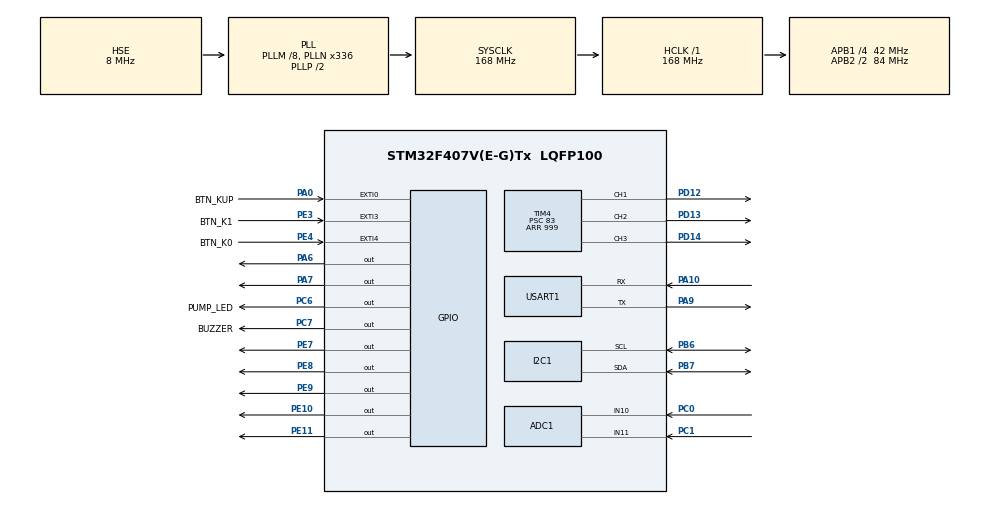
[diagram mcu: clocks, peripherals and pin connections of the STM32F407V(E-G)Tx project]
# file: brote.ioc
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ADC1.Channel-2\#ChannelRegularConversion=ADC_CHANNEL_10
ADC1.NbrOfConversionFlag=1
ADC1.Rank-2\#ChannelRegularConversion=1
ADC1.SamplingTime-2\#ChannelRegularConversion=ADC_SAMPLETIME_3CYCLES
ADC1.master=1
Dma.Request0=USART1_TX
Dma.USART1_TX.0.Direction=DMA_MEMORY_TO_PERIPH
Dma.USART1_TX.0.FIFOMode=DMA_FIFOMODE_DISABLE
Dma.USART1_TX.0.Instance=DMA2_Stream7
Dma.USART1_TX.0.MemDataAlignment=DMA_MDATAALIGN_BYTE
Dma.USART1_TX.0.MemInc=DMA_MINC_ENABLE
Dma.USART1_TX.0.Mode=DMA_NORMAL
Dma.USART1_TX.0.PeriphDataAlignment=DMA_PDATAALIGN_BYTE
Dma.USART1_TX.0.PeriphInc=DMA_PINC_DISABLE
Dma.USART1_TX.0.Priority=DMA_PRIORITY_LOW
FREERTOS.Mutexes01=mtxI2C,Dynamic,NULL,Available;mtxData,Dynamic,NULL,Available
FREERTOS.Queues01=qEvents,8,app_event_t,0,Dynamic,NULL,NULL;qLog,16,log_msg_t,0,Dynamic,NULL,NULL
FREERTOS.Tasks01=tActuators,40,256,StartActuatorsTask,As weak,NULL,Dynamic,NULL,NULL;tControl,32,256,StartControlTask,As weak,NULL,Dynamic,NULL,NULL;tSensors,24,256,StartSensorsTask,As weak,NULL,Dynamic,NULL,NULL;tDisplay,16,384,StartDisplayTask,As weak,NULL,Dynamic,NULL,NULL;tLogger,8,384,StartLoggerTask,As weak,NULL,Dynamic,NULL,NULL
FREERTOS.configCHECK_FOR_STACK_OVERFLOW=2
FREERTOS.configTOTAL_HEAP_SIZE=32768
FREERTOS.configUSE_NEWLIB_REENTRANT=1
I2C1.I2C_Mode=I2C_Fast
Mcu.Family=STM32F4
Mcu.Name=STM32F407V(E-G)Tx
Mcu.Package=LQFP100
NVIC.DMA2_Stream7_IRQn=true\:5\:0\:false\:false\:true\:true\:false\:true\:true
NVIC.EXTI0_IRQn=true\:6\:0\:true\:false\:true\:true\:true\:true\:true
NVIC.EXTI3_IRQn=true\:6\:0\:true\:false\:true\:true\:true\:true\:true
NVIC.EXTI4_IRQn=true\:6\:0\:true\:false\:true\:true\:true\:true\:true
NVIC.PriorityGroup=NVIC_PRIORITYGROUP_4
NVIC.TimeBase=TIM6_DAC_IRQn
NVIC.TimeBaseIP=TIM6
NVIC.USART1_IRQn=true\:5\:0\:false\:false\:true\:true\:false\:true\:true
PA0-WKUP.GPIO_Label=BTN_KUP
PA0-WKUP.GPIO_ModeDefaultEXTI=GPIO_MODE_IT_RISING
PA0-WKUP.GPIO_PuPd=GPIO_PULLDOWN
PA0-WKUP.Signal=GPXTI0
PA10.Mode=Asynchronous
PA10.Signal=USART1_RX
PA13.Mode=Serial_Wire
PA13.Signal=SYS_JTMS-SWDIO
PA14.Mode=Serial_Wire
PA14.Signal=SYS_JTCK-SWCLK
PA6.PinState=GPIO_PIN_SET
PA6.Signal=GPIO_Output
PA7.PinState=GPIO_PIN_SET
PA7.Signal=GPIO_Output
PA9.Mode=Asynchronous
PA9.Signal=USART1_TX
PB6.Mode=I2C
PB6.Signal=I2C1_SCL
PB7.Mode=I2C
PB7.Signal=I2C1_SDA
PC0.Signal=ADCx_IN10
PC1.Signal=ADCx_IN11
PC6.GPIO_Label=PUMP_LED
PC6.Signal=GPIO_Output
PC7.GPIO_Label=BUZZER
PC7.PinState=GPIO_PIN_SET
PC7.Signal=GPIO_Output
PD12.Signal=S_TIM4_CH1
PD13.Signal=S_TIM4_CH2
PD14.Signal=S_TIM4_CH3
PE10.Signal=GPIO_Output
PE11.Signal=GPIO_Output
PE3.GPIO_Label=BTN_K1
PE3.GPIO_ModeDefaultEXTI=GPIO_MODE_IT_FALLING
PE3.GPIO_PuPd=GPIO_PULLUP
PE3.Signal=GPXTI3
PE4.GPIO_Label=BTN_K0
PE4.GPIO_ModeDefaultEXTI=GPIO_MODE_IT_FALLING
PE4.GPIO_PuPd=GPIO_PULLUP
PE4.Signal=GPXTI4
PE7.Signal=GPIO_Output
PE8.Signal=GPIO_Output
PE9.Signal=GPIO_Output
PH0-OSC_IN.Mode=HSE-External-Oscillator
PH0-OSC_IN.Signal=RCC_OSC_IN
PH1-OSC_OUT.Mode=HSE-External-Oscillator
PH1-OSC_OUT.Signal=RCC_OSC_OUT
ProjectManager.HeapSize=0x200
ProjectManager.StackSize=0x400
ProjectManager.TargetToolchain=STM32CubeIDE
RCC.48MHZClocksFreq_Value=84000000
RCC.AHBFreq_Value=168000000
RCC.APB1CLKDivider=RCC_HCLK_DIV4
RCC.APB1Freq_Value=42000000
RCC.APB1TimFreq_Value=84000000
RCC.APB2CLKDivider=RCC_HCLK_DIV2
RCC.APB2Freq_Value=84000000
RCC.APB2TimFreq_Value=168000000
RCC.CortexFreq_Value=168000000
RCC.EnbaleCSS=true
RCC.HCLKFreq_Value=168000000
RCC.HSE_VALUE=8000000
RCC.HSI_VALUE=16000000
RCC.LSE_VALUE=32768
RCC.PLLM=8
RCC.PLLN=336
RCC.PLLSourceVirtual=RCC_PLLSOURCE_HSE
RCC.SYSCLKFreq_VALUE=168000000
RCC.SYSCLKSource=RCC_SYSCLKSOURCE_PLLCLK
RCC.VCOOutputFreq_Value=336000000
SH.ADCx_IN10.0=ADC1_IN10,IN10
SH.ADCx_IN11.0=ADC1_IN11,IN11
SH.S_TIM4_CH1.0=TIM4_CH1,PWM Generation1 CH1
SH.S_TIM4_CH2.0=TIM4_CH2,PWM Generation2 CH2
SH.S_TIM4_CH3.0=TIM4_CH3,PWM Generation3 CH3
TIM4.Channel-PWM\ Generation1\ CH1=TIM_CHANNEL_1
TIM4.Channel-PWM\ Generation2\ CH2=TIM_CHANNEL_2
TIM4.Channel-PWM\ Generation3\ CH3=TIM_CHANNEL_3
TIM4.Period=999
TIM4.Prescaler=83
USART1.VirtualMode=VM_ASYNC
VP_FREERTOS_VS_CMSIS_V2.Mode=CMSIS_V2
VP_SYS_VS_tim6.Mode=TIM6
board=custom

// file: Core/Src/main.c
/* USER CODE BEGIN Header */
/**
  ******************************************************************************
  * @file           : main.c
  * @brief          : Main program body
  ******************************************************************************
  * @attention
  *
  * Copyright (c) 2026 STMicroelectronics.
  * All rights reserved.
  *
  * This software is licensed under terms that can be found in the LICENSE file
  * in the root directory of this software component.
  * If no LICENSE file comes with this software, it is provided AS-IS.
  *
  ******************************************************************************
  */
/* USER CODE END Header */
#include "main.h"
#include "cmsis_os.h"
#include "adc.h"
#include "dma.h"
#include "i2c.h"
#include "tim.h"
#include "usart.h"
#include "gpio.h"

void SystemClock_Config(void);
void MX_FREERTOS_Init(void);

int main(void)
{

  /* MCU Configuration--------------------------------------------------------*/

  /* Reset of all peripherals, Initializes the Flash interface and the Systick. */
  HAL_Init();

  /* Configure the system clock */
  SystemClock_Config();

  /* Initialize all configured peripherals */
  MX_GPIO_Init();
  MX_DMA_Init();
  MX_ADC1_Init();
  MX_USART1_UART_Init();
  MX_I2C1_Init();
  MX_TIM4_Init();

  /* Init scheduler */
  osKernelInitialize();  /* Call init function for freertos objects (in cmsis_os2.c) */
  MX_FREERTOS_Init();

  /* Start scheduler */
  osKernelStart();

  /* We should never get here as control is now taken by the scheduler */

  /* Infinite loop */
  while (1)
  {

  }
}

void SystemClock_Config(void)
{
  RCC_OscInitTypeDef RCC_OscInitStruct = {0};
  RCC_ClkInitTypeDef RCC_ClkInitStruct = {0};

  /** Configure the main internal regulator output voltage
  */
  __HAL_RCC_PWR_CLK_ENABLE();
  __HAL_PWR_VOLTAGESCALING_CONFIG(PWR_REGULATOR_VOLTAGE_SCALE1);

  /** Initializes the RCC Oscillators according to the specified parameters
  * in the RCC_OscInitTypeDef structure.
  */
  RCC_OscInitStruct.OscillatorType = RCC_OSCILLATORTYPE_HSE;
  RCC_OscInitStruct.HSEState = RCC_HSE_ON;
  RCC_OscInitStruct.PLL.PLLState = RCC_PLL_ON;
  RCC_OscInitStruct.PLL.PLLSource = RCC_PLLSOURCE_HSE;
  RCC_OscInitStruct.PLL.PLLM = 8;
  RCC_OscInitStruct.PLL.PLLN = 336;
  RCC_OscInitStruct.PLL.PLLP = RCC_PLLP_DIV2;
  RCC_OscInitStruct.PLL.PLLQ = 4;
  if (HAL_RCC_OscConfig(&RCC_OscInitStruct) != HAL_OK)
  {
    Error_Handler();
  }

  /** Initializes the CPU, AHB and APB buses clocks
  */
  RCC_ClkInitStruct.ClockType = RCC_CLOCKTYPE_HCLK|RCC_CLOCKTYPE_SYSCLK
                              |RCC_CLOCKTYPE_PCLK1|RCC_CLOCKTYPE_PCLK2;
  RCC_ClkInitStruct.SYSCLKSource = RCC_SYSCLKSOURCE_PLLCLK;
  RCC_ClkInitStruct.AHBCLKDivider = RCC_SYSCLK_DIV1;
  RCC_ClkInitStruct.APB1CLKDivider = RCC_HCLK_DIV4;
  RCC_ClkInitStruct.APB2CLKDivider = RCC_HCLK_DIV2;

  if (HAL_RCC_ClockConfig(&RCC_ClkInitStruct, FLASH_LATENCY_5) != HAL_OK)
  {
    Error_Handler();
  }

  /** Enables the Clock Security System
  */
  HAL_RCC_EnableCSS();
}

void HAL_TIM_PeriodElapsedCallback(TIM_HandleTypeDef *htim)
{
  if (htim->Instance == TIM6)
  {
    HAL_IncTick();
  }
}

void Error_Handler(void)
{
  __disable_irq();
  while (1)
  {
  }
}

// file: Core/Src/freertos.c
/* USER CODE BEGIN Header */
/**
  ******************************************************************************
  * File Name          : freertos.c
  * Description        : Code for freertos applications
  ******************************************************************************
  * @attention
  *
  * Copyright (c) 2026 STMicroelectronics.
  * All rights reserved.
  *
  * This software is licensed under terms that can be found in the LICENSE file
  * in the root directory of this software component.
  * If no LICENSE file comes with this software, it is provided AS-IS.
  *
  ******************************************************************************
  */
/* USER CODE END Header */

#include "FreeRTOS.h"
#include "task.h"
#include "main.h"
#include "cmsis_os.h"

/* USER CODE BEGIN Includes */
#include "app_types.h"      /* app_event_t: Item Size de qEvents */
#include "task_logger.h"    /* log_msg_t: Item Size de qLog */
#include "task_actuators.h" /* act_fatal_stack_overflow */

/* USER CODE END Includes */

/* Definitions for tActuators */
osThreadId_t tActuatorsHandle;
const osThreadAttr_t tActuators_attributes = {
  .name = "tActuators",
  .stack_size = 256 * 4,
  .priority = (osPriority_t) osPriorityHigh,
};
/* Definitions for tControl */
osThreadId_t tControlHandle;
const osThreadAttr_t tControl_attributes = {
  .name = "tControl",
  .stack_size = 256 * 4,
  .priority = (osPriority_t) osPriorityAboveNormal,
};
/* Definitions for tSensors */
osThreadId_t tSensorsHandle;
const osThreadAttr_t tSensors_attributes = {
  .name = "tSensors",
  .stack_size = 256 * 4,
  .priority = (osPriority_t) osPriorityNormal,
};
/* Definitions for tDisplay */
osThreadId_t tDisplayHandle;
const osThreadAttr_t tDisplay_attributes = {
  .name = "tDisplay",
  .stack_size = 384 * 4,
  .priority = (osPriority_t) osPriorityBelowNormal,
};
/* Definitions for tLogger */
osThreadId_t tLoggerHandle;
const osThreadAttr_t tLogger_attributes = {
  .name = "tLogger",
  .stack_size = 384 * 4,
  .priority = (osPriority_t) osPriorityLow,
};
/* Definitions for qEvents */
osMessageQueueId_t qEventsHandle;
const osMessageQueueAttr_t qEvents_attributes = {
  .name = "qEvents"
};
/* Definitions for qLog */
osMessageQueueId_t qLogHandle;
const osMessageQueueAttr_t qLog_attributes = {
  .name = "qLog"
};
/* Definitions for mtxI2C */
osMutexId_t mtxI2CHandle;
const osMutexAttr_t mtxI2C_attributes = {
  .name = "mtxI2C"
};
/* Definitions for mtxData */
osMutexId_t mtxDataHandle;
const osMutexAttr_t mtxData_attributes = {
  .name = "mtxData"
};

void StartActuatorsTask(void *argument);
void StartControlTask(void *argument);
void StartSensorsTask(void *argument);
void StartDisplayTask(void *argument);
void StartLoggerTask(void *argument);

void MX_FREERTOS_Init(void); /* (MISRA C 2004 rule 8.1) */

/* Hook prototypes */
void vApplicationStackOverflowHook(xTaskHandle xTask, signed char *pcTaskName);

/* USER CODE BEGIN 4 */
void vApplicationStackOverflowHook(xTaskHandle xTask, signed char *pcTaskName)
{
   /* Run time stack overflow checking is performed if
   configCHECK_FOR_STACK_OVERFLOW is defined to 1 or 2. This hook function is
   called if a stack overflow is detected. */
   (void)xTask;
   (void)pcTaskName;
   act_fatal_stack_overflow();     /* bomba y buzzer apagados, LED rojo fijo; no retorna */
}
/* USER CODE END 4 */

void MX_FREERTOS_Init(void) {
  /* Create the mutex(es) */
  /* creation of mtxI2C */
  mtxI2CHandle = osMutexNew(&mtxI2C_attributes);

  /* creation of mtxData */
  mtxDataHandle = osMutexNew(&mtxData_attributes);

  /* Create the queue(s) */
  /* creation of qEvents */
  qEventsHandle = osMessageQueueNew (8, sizeof(app_event_t), &qEvents_attributes);

  /* creation of qLog */
  qLogHandle = osMessageQueueNew (16, sizeof(log_msg_t), &qLog_attributes);

  /* Create the thread(s) */
  /* creation of tActuators */
  tActuatorsHandle = osThreadNew(StartActuatorsTask, NULL, &tActuators_attributes);

  /* creation of tControl */
  tControlHandle = osThreadNew(StartControlTask, NULL, &tControl_attributes);

  /* creation of tSensors */
  tSensorsHandle = osThreadNew(StartSensorsTask, NULL, &tSensors_attributes);

  /* creation of tDisplay */
  tDisplayHandle = osThreadNew(StartDisplayTask, NULL, &tDisplay_attributes);

  /* creation of tLogger */
  tLoggerHandle = osThreadNew(StartLoggerTask, NULL, &tLogger_attributes);

}

__weak void StartActuatorsTask(void *argument)
{
  for(;;)
  {
    osDelay(1);
  }
}

__weak void StartControlTask(void *argument)
{
  for(;;)
  {
    osDelay(1);
  }
}

__weak void StartSensorsTask(void *argument)
{
  for(;;)
  {
    osDelay(1);
  }
}

__weak void StartDisplayTask(void *argument)
{
  for(;;)
  {
    osDelay(1);
  }
}

__weak void StartLoggerTask(void *argument)
{
  for(;;)
  {
    osDelay(1);
  }
}
